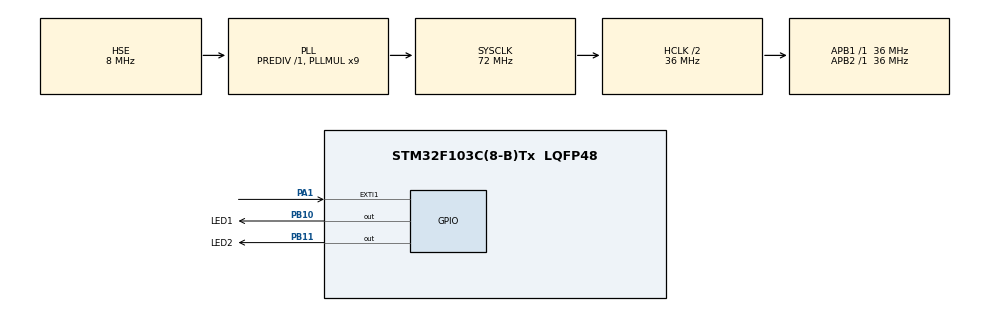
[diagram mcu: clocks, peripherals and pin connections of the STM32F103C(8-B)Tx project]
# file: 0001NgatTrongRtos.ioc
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FREERTOS.Tasks01=defaultTask,0,128,TaskMacDinh,Default,NULL,Dynamic,NULL,NULL
Mcu.Family=STM32F1
Mcu.Name=STM32F103C(8-B)Tx
Mcu.Package=LQFP48
NVIC.EXTI1_IRQn=true\:5\:0\:false\:false\:true\:true\:true\:true
NVIC.PriorityGroup=NVIC_PRIORITYGROUP_4
NVIC.TIM4_IRQn=true\:15\:0\:false\:false\:true\:false\:false\:true
NVIC.TimeBase=TIM4_IRQn
NVIC.TimeBaseIP=TIM4
PA1.GPIO_ModeDefaultEXTI=GPIO_MODE_IT_FALLING
PA1.GPIO_PuPd=GPIO_PULLUP
PA1.Signal=GPXTI1
PA13.Mode=Serial_Wire
PA13.Signal=SYS_JTMS-SWDIO
PA14.Mode=Serial_Wire
PA14.Signal=SYS_JTCK-SWCLK
PB10.GPIO_Label=LED1
PB10.Signal=GPIO_Output
PB11.GPIO_Label=LED2
PB11.Signal=GPIO_Output
PD0-OSC_IN.Mode=HSE-External-Oscillator
PD0-OSC_IN.Signal=RCC_OSC_IN
PD1-OSC_OUT.Mode=HSE-External-Oscillator
PD1-OSC_OUT.Signal=RCC_OSC_OUT
ProjectManager.HeapSize=0x200
ProjectManager.StackSize=0x400
ProjectManager.TargetToolchain=STM32CubeIDE
RCC.AHBCLKDivider=RCC_SYSCLK_DIV2
RCC.AHBFreq_Value=36000000
RCC.APB1Freq_Value=36000000
RCC.APB1TimFreq_Value=36000000
RCC.APB2Freq_Value=36000000
RCC.APB2TimFreq_Value=36000000
RCC.HCLKFreq_Value=36000000
RCC.PLLMUL=RCC_PLL_MUL9
RCC.PLLSourceVirtual=RCC_PLLSOURCE_HSE
RCC.SYSCLKFreq_VALUE=72000000
RCC.SYSCLKSource=RCC_SYSCLKSOURCE_PLLCLK
RCC.USBFreq_Value=72000000
VP_FREERTOS_VS_CMSIS_V1.Mode=CMSIS_V1
VP_SYS_VS_tim4.Mode=TIM4
board=custom

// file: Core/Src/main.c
/* USER CODE BEGIN Header */
/**
  ******************************************************************************
  * @file           : main.c
  * @brief          : Main program body
  ******************************************************************************
  * @attention
  *
  * <h2><center>&copy; Copyright (c) 2022 STMicroelectronics.
  * All rights reserved.</center></h2>
  *
  * This software component is licensed by ST under BSD 3-Clause license,
  * the "License"; You may not use this file except in compliance with the
  * License. You may obtain a copy of the License at:
  *                        opensource.org/licenses/BSD-3-Clause
  *
  ******************************************************************************
  */
/* USER CODE END Header */
#include "main.h"
#include "cmsis_os.h"

osThreadId defaultTaskHandle;

TaskHandle_t Task1Handle;

void SystemClock_Config(void);
static void MX_GPIO_Init(void);
void TaskMacDinh(void const * argument);

/* USER CODE BEGIN PFP */
void Task1Func(void *Param);
/* USER CODE END PFP */

int main(void)
{

  /* MCU Configuration--------------------------------------------------------*/

  /* Reset of all peripherals, Initializes the Flash interface and the Systick. */
  HAL_Init();

  /* Configure the system clock */
  SystemClock_Config();

  /* Initialize all configured peripherals */
  MX_GPIO_Init();

  /* Create the thread(s) */
  /* definition and creation of defaultTask */
  osThreadDef(defaultTask, TaskMacDinh, osPriorityNormal, 0, 128);
  defaultTaskHandle = osThreadCreate(osThread(defaultTask), NULL);

  /* USER CODE BEGIN RTOS_THREADS */
  /* add threads, ... */
  xTaskCreate(Task1Func, "task1", 128, NULL, osPriorityAboveNormal + 3, &Task1Handle);
  /* USER CODE END RTOS_THREADS */

  /* Start scheduler */
  osKernelStart();

  /* We should never get here as control is now taken by the scheduler */
  /* Infinite loop */
  while (1)
  {

  }
}

void SystemClock_Config(void)
{
  RCC_OscInitTypeDef RCC_OscInitStruct = {0};
  RCC_ClkInitTypeDef RCC_ClkInitStruct = {0};

  /** Initializes the RCC Oscillators according to the specified parameters
  * in the RCC_OscInitTypeDef structure.
  */
  RCC_OscInitStruct.OscillatorType = RCC_OSCILLATORTYPE_HSE;
  RCC_OscInitStruct.HSEState = RCC_HSE_ON;
  RCC_OscInitStruct.HSEPredivValue = RCC_HSE_PREDIV_DIV1;
  RCC_OscInitStruct.HSIState = RCC_HSI_ON;
  RCC_OscInitStruct.PLL.PLLState = RCC_PLL_ON;
  RCC_OscInitStruct.PLL.PLLSource = RCC_PLLSOURCE_HSE;
  RCC_OscInitStruct.PLL.PLLMUL = RCC_PLL_MUL9;
  if (HAL_RCC_OscConfig(&RCC_OscInitStruct) != HAL_OK)
  {
    Error_Handler();
  }
  /** Initializes the CPU, AHB and APB buses clocks
  */
  RCC_ClkInitStruct.ClockType = RCC_CLOCKTYPE_HCLK|RCC_CLOCKTYPE_SYSCLK
                              |RCC_CLOCKTYPE_PCLK1|RCC_CLOCKTYPE_PCLK2;
  RCC_ClkInitStruct.SYSCLKSource = RCC_SYSCLKSOURCE_PLLCLK;
  RCC_ClkInitStruct.AHBCLKDivider = RCC_SYSCLK_DIV2;
  RCC_ClkInitStruct.APB1CLKDivider = RCC_HCLK_DIV1;
  RCC_ClkInitStruct.APB2CLKDivider = RCC_HCLK_DIV1;

  if (HAL_RCC_ClockConfig(&RCC_ClkInitStruct, FLASH_LATENCY_2) != HAL_OK)
  {
    Error_Handler();
  }
}

static void MX_GPIO_Init(void)
{
  GPIO_InitTypeDef GPIO_InitStruct = {0};

  /* GPIO Ports Clock Enable */
  __HAL_RCC_GPIOD_CLK_ENABLE();
  __HAL_RCC_GPIOA_CLK_ENABLE();
  __HAL_RCC_GPIOB_CLK_ENABLE();

  /*Configure GPIO pin Output Level */
  HAL_GPIO_WritePin(GPIOB, LED1_Pin|LED2_Pin, GPIO_PIN_RESET);

  /*Configure GPIO pin : PA1 */
  GPIO_InitStruct.Pin = GPIO_PIN_1;
  GPIO_InitStruct.Mode = GPIO_MODE_IT_FALLING;
  GPIO_InitStruct.Pull = GPIO_PULLUP;
  HAL_GPIO_Init(GPIOA, &GPIO_InitStruct);

  /*Configure GPIO pins : LED1_Pin LED2_Pin */
  GPIO_InitStruct.Pin = LED1_Pin|LED2_Pin;
  GPIO_InitStruct.Mode = GPIO_MODE_OUTPUT_PP;
  GPIO_InitStruct.Pull = GPIO_NOPULL;
  GPIO_InitStruct.Speed = GPIO_SPEED_FREQ_LOW;
  HAL_GPIO_Init(GPIOB, &GPIO_InitStruct);

  /* EXTI interrupt init*/
  HAL_NVIC_SetPriority(EXTI1_IRQn, 5, 0);
  HAL_NVIC_EnableIRQ(EXTI1_IRQn);

}

/* USER CODE BEGIN 4 */
void HAL_GPIO_EXIT_Callback(uint16_t GPIO_Pin)
{
	BaseType_t xHigherPriority;
	xHigherPriority = xTaskResumeFromISR(defaultTaskHandle);
	portEND_SWITCHING_ISR(xHigherPriority);
}
void Task1Func(void * Param)
{
  /* USER CODE BEGIN 5 */

  /* Infinite loop */
  for(;;)
  {
	  vTaskSuspend(Task1Handle);
	  HAL_GPIO_WritePin(LED2_GPIO_Port, LED2_Pin, 1);

  }
  /* USER CODE END 5 */
}
/* USER CODE END 4 */

void TaskMacDinh(void const * argument)
{
  /* USER CODE BEGIN 5 */
	vTaskSuspend(defaultTaskHandle);
  /* Infinite loop */
  for(;;)
  {
    HAL_GPIO_WritePin(LED1_GPIO_Port, LED1_Pin, 1);
    osDelay(2000);
  }
  /* USER CODE END 5 */
}

void HAL_TIM_PeriodElapsedCallback(TIM_HandleTypeDef *htim)
{
  if (htim->Instance == TIM4) {
    HAL_IncTick();
  }
}

void Error_Handler(void)
{
  __disable_irq();
  while (1)
  {
  }
}

/************************ (C) COPYRIGHT STMicroelectronics *****END OF FILE****/
